AUTOSAR XML (schema 00050)
package /VectorAutosarExplorerGeneratedObjects/SYSTEM
  system System
package /VectorAutosarExplorerGeneratedObjects/Comfort
  can cluster Comfort: baudrate=500000, protocol-name=CAN, speed=250000
    can physical channel CANChannel: comm-connectors=Connector_Fan_ECU_fbc5880ce1a0cdea
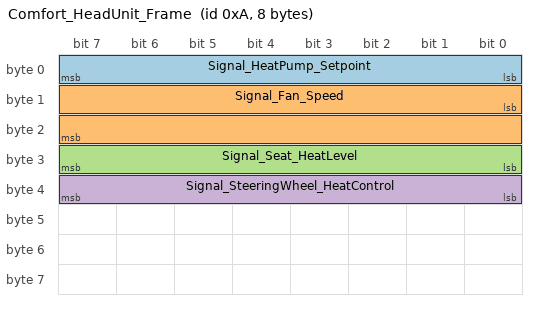
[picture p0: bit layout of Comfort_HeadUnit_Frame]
      frame Comfort_HeadUnit_Frame: id 0xA, to Fan_ECU, frame-length=8, can-addressing-mode=STANDARD, can-frame-tx-behavior=CAN-20
        pdu Comfort_HeadUnit_Frame_PDU: length=8, transmission-mode-true-timing=cyclic-timing=time-period=0.1
          signal Signal_HeatPump_Setpoint: start 0, 8 bit, little-endian, system signal Signal_HeatPump_Setpoint_128f28339b77454b, data-type-policy=OVERRIDE, base-type=Temperature_BaseType, compu {phys=raw for raw 10..30; unit °C}
          signal Signal_Fan_Speed: start 8, 16 bit, little-endian, system signal Signal_Fan_Setpoint_7226b1dfc825beac, data-type-policy=OVERRIDE, base-type=Speed_BaseType, compu {phys=raw for raw 0..3500; unit RPM}, to Fan_ECU
          signal Signal_Seat_HeatLevel: start 24, 8 bit, little-endian, system signal Signal_Seat_HeatLevel_70084504bb35d07f, data-type-policy=OVERRIDE, base-type=Temperature_BaseType, compu {0=Off, 1=Minimum (Low), 2=Medium, 3=Maximum (High)}
          signal Signal_SteeringWheel_HeatControl: start 32, 8 bit, little-endian, system signal Signal_SteeringWheel_HeatControl_7a6769d229411a8c, data-type-policy=OVERRIDE, base-type=Temperature_BaseType, compu {1=Enabled (On), 0=Disabled (Off)}
      frame Comfort_Fan_Frame: id 0x2, from Fan_ECU, frame-length=8, can-addressing-mode=STANDARD, can-frame-tx-behavior=CAN-20
        pdu Comfort_Fan_Frame_PDU: length=8, transmission-mode-true-timing=cyclic-timing=time-period=1
          signal Signal_Fan_Fault: start 0, 8 bit, little-endian, system signal Signal_Fan_Fault_f777c54e31a89d5c, data-type-policy=OVERRIDE, base-type=Temperature_BaseType, compu {1=Faulty, 0=NormalOperation}, transfer-property=TRIGGERED-ON-CHANGE
      frame Comfort_Fan_NM_Tx: id 0x6, from Fan_ECU, frame-length=8, can-addressing-mode=STANDARD, can-frame-tx-behavior=CAN-20
        nm pdu Comfort_Fan_NM_PDU_Tx: length=8
      frame Comfort_Fan_NM_Rx: id 0x7, to Fan_ECU, frame-length=8, can-addressing-mode=STANDARD, can-frame-tx-behavior=CAN-20
        nm pdu Comfort_Fan_NM_PDU_Rx: length=8
      frame Comfort_TP_Diag_Request_Fan_ECU_Frame: id 0x1, to Fan_ECU, frame-length=8, can-addressing-mode=STANDARD, can-frame-tx-behavior=CAN-20
        n pdu Comfort_TP_Diag_Request_Fan_ECU_Frame_PDU: length=8
      frame Comfort_TP_Diag_Response_Fan_ECU_Frame: id 0x8, from Fan_ECU, frame-length=8, can-addressing-mode=STANDARD, can-frame-tx-behavior=CAN-20
        n pdu Comfort_TP_Diag_Response_Fan_ECU_Frame_PDU: length=8
      frame Comfort_DrivingCycle_Frame: id 0x9, to Fan_ECU, frame-length=8, can-addressing-mode=STANDARD, can-frame-tx-behavior=CAN-20
        pdu Comfort_DrivingCycle_Frame_PDU: length=8
          signal Signal_DrivingCycle: start 0, 8 bit, little-endian, system signal Signal_Comfort_DrivingCycle_d5cecd98dc1c368d, data-type-policy=OVERRIDE, base-type=Temperature_BaseType, compu {1=Start Driving Cycle (START), 0=Stop Driving Cycle (STOP)}, to Fan_ECU
      pdu triggering PduTriggering_FanDiagnostic_Request: pdu=Diag_Request_Fan_ECU_PDU, to Fan_ECU
      pdu triggering PduTriggering_FanDiagnostic_Response: pdu=Diag_Response_Fan_ECU_PDU, from Fan_ECU
package /VectorAutosarExplorerGeneratedObjects/ECU_INSTANCES
  ecu instance Fan_ECU: associated-com-i-pdu-group=[PduGroup_0d620c5c31e9468c805e953e49743e0a_Rx, PduGroup_74671e2bef9a450f9b76d8edb8306b91_Tx, PduGroup_e08cbf222c5049fa934c8feff94811d6_Rx], diagnostic-address=0
    can communication controller Controller_Fan_ECU_02f7c8db915351a9
    can communication connector Connector_Fan_ECU_fbc5880ce1a0cdea: comm-controller=Controller_Fan_ECU_02f7c8db915351a9
package /VectorAutosarExplorerGeneratedObjects/PDUS
  dcm i pdu Diag_Request_Fan_ECU_PDU: length=8, diag-pdu-type=DIAG-REQUEST
  dcm i pdu Diag_Response_Fan_ECU_PDU: length=8, diag-pdu-type=DIAG-RESPONSE
package /VectorAutosarExplorerGeneratedObjects/BASE_TYPES
  base type Temperature_BaseType: base-type-size=16, base-type-encoding=2C
  base type Speed_BaseType: base-type-size=16, base-type-encoding=NONE
package /VectorAutosarExplorerGeneratedObjects/PDU_GROUP
  i signal i pdu group PduGroup_0d620c5c31e9468c805e953e49743e0a_Rx: communication-direction=IN
  i signal i pdu group PduGroup_74671e2bef9a450f9b76d8edb8306b91_Tx: communication-direction=OUT
  i signal i pdu group PduGroup_e08cbf222c5049fa934c8feff94811d6_Rx: communication-direction=IN
package /VectorAutosarExplorerGeneratedObjects/UNIT
  unit Celsius: display-name=°C  # DegreeCelsius
  unit RPM: display-name=RPM
